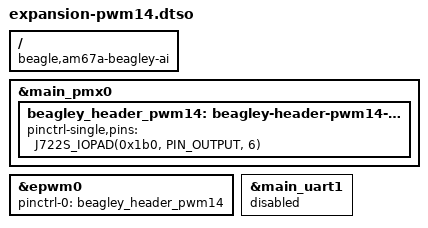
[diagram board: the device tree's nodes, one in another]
// SPDX-License-Identifier: GPL-2.0-only OR MIT
/* BeagleY-AI header routes adapted from BeagleBoard.org DeviceTrees.
 * Copyright (C) BeagleBoard.org Foundation
 * See docs/expansion.md for the pinned source and connector identities.
 */
/dts-v1/;
/plugin/;
#include <dt-bindings/gpio/gpio.h>
#include <arm64/ti/k3-pinctrl.h>
/ { compatible = "beagle,am67a-beagley-ai"; };
&main_pmx0 {
  beagley_header_pwm14: beagley-header-pwm14-pins {
    pinctrl-single,pins = <J722S_IOPAD(0x1b0, PIN_OUTPUT, 6)>;
  };
};
&epwm0 { pinctrl-names = "default"; pinctrl-0 = <&beagley_header_pwm14>; status = "okay"; };
&main_uart1 { status = "disabled"; };
